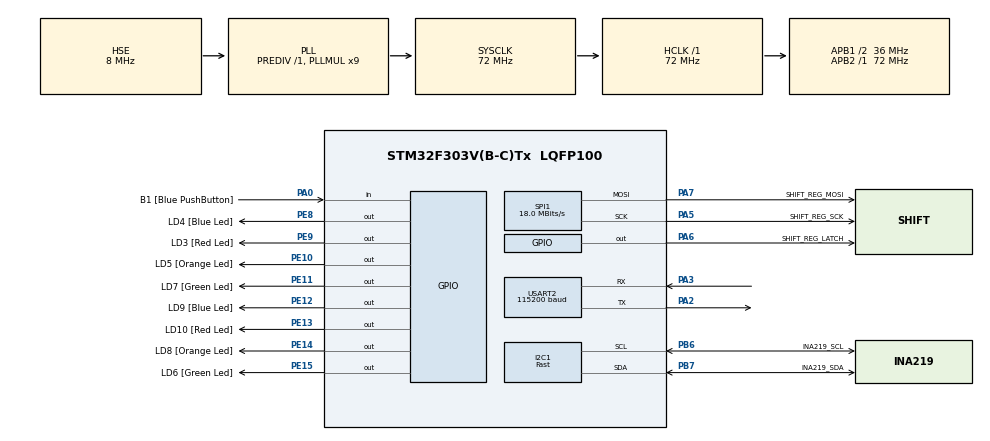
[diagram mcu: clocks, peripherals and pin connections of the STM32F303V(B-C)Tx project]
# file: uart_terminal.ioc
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Dma.Request0=USART2_TX
Dma.Request1=USART2_RX
Dma.Request2=SPI1_TX
Dma.SPI1_TX.2.Direction=DMA_MEMORY_TO_PERIPH
Dma.SPI1_TX.2.Instance=DMA1_Channel3
Dma.SPI1_TX.2.MemDataAlignment=DMA_MDATAALIGN_BYTE
Dma.SPI1_TX.2.MemInc=DMA_MINC_ENABLE
Dma.SPI1_TX.2.Mode=DMA_NORMAL
Dma.SPI1_TX.2.PeriphDataAlignment=DMA_PDATAALIGN_BYTE
Dma.SPI1_TX.2.PeriphInc=DMA_PINC_DISABLE
Dma.SPI1_TX.2.Priority=DMA_PRIORITY_MEDIUM
Dma.USART2_RX.1.Direction=DMA_PERIPH_TO_MEMORY
Dma.USART2_RX.1.Instance=DMA1_Channel6
Dma.USART2_RX.1.MemDataAlignment=DMA_MDATAALIGN_BYTE
Dma.USART2_RX.1.MemInc=DMA_MINC_ENABLE
Dma.USART2_RX.1.Mode=DMA_NORMAL
Dma.USART2_RX.1.PeriphDataAlignment=DMA_PDATAALIGN_BYTE
Dma.USART2_RX.1.PeriphInc=DMA_PINC_DISABLE
Dma.USART2_RX.1.Priority=DMA_PRIORITY_HIGH
Dma.USART2_TX.0.Direction=DMA_MEMORY_TO_PERIPH
Dma.USART2_TX.0.Instance=DMA1_Channel7
Dma.USART2_TX.0.MemDataAlignment=DMA_MDATAALIGN_BYTE
Dma.USART2_TX.0.MemInc=DMA_MINC_ENABLE
Dma.USART2_TX.0.Mode=DMA_NORMAL
Dma.USART2_TX.0.PeriphDataAlignment=DMA_PDATAALIGN_BYTE
Dma.USART2_TX.0.PeriphInc=DMA_PINC_DISABLE
Dma.USART2_TX.0.Priority=DMA_PRIORITY_HIGH
I2C1.I2C_Speed_Mode=I2C_Fast
I2C1.Timing=0x0000020B
Mcu.Family=STM32F3
Mcu.Name=STM32F303V(B-C)Tx
Mcu.Package=LQFP100
NVIC.DMA1_Channel3_IRQn=true\:0\:0\:false\:false\:true\:false\:true
NVIC.DMA1_Channel6_IRQn=true\:0\:0\:false\:false\:true\:false\:true
NVIC.DMA1_Channel7_IRQn=true\:0\:0\:false\:false\:true\:false\:true
NVIC.I2C1_ER_IRQn=true\:0\:0\:false\:false\:true\:true\:true
NVIC.I2C1_EV_IRQn=true\:0\:0\:false\:false\:true\:true\:true
NVIC.PriorityGroup=NVIC_PRIORITYGROUP_0
NVIC.SPI1_IRQn=true\:0\:0\:false\:false\:true\:true\:true
NVIC.TIM2_IRQn=true\:0\:0\:false\:false\:true\:true\:true
NVIC.USART2_IRQn=true\:0\:0\:false\:false\:true\:true\:true
PA0.GPIO_Label=B1 [Blue PushButton]
PA0.Signal=GPIO_Input
PA11.GPIO_Label=DM
PA11.Signal=USB_DM
PA12.GPIO_Label=DP
PA12.Signal=USB_DP
PA13.GPIO_Label=SWDIO
PA13.Mode=Serial_Wire
PA13.Signal=SYS_JTMS-SWDIO
PA14.GPIO_Label=SWCLK
PA14.Mode=Serial_Wire
PA14.Signal=SYS_JTCK-SWCLK
PA2.Mode=Asynchronous
PA2.Signal=USART2_TX
PA3.Mode=Asynchronous
PA3.Signal=USART2_RX
PA5.GPIO_Label=SHIFT_REG_SCK
PA5.Mode=TX_Only_Simplex_Unidirect_Master
PA5.Signal=SPI1_SCK
PA6.GPIO_Label=SHIFT_REG_LATCH
PA6.GPIO_PuPd=GPIO_PULLUP
PA6.GPIO_Speed=GPIO_SPEED_FREQ_HIGH
PA6.Signal=GPIO_Output
PA7.GPIO_Label=SHIFT_REG_MOSI
PA7.Mode=TX_Only_Simplex_Unidirect_Master
PA7.Signal=SPI1_MOSI
PB3.GPIO_Label=SWO
PB3.Signal=SYS_JTDO-TRACESWO
PB6.GPIO_Label=INA219_SCL
PB6.Mode=I2C
PB6.Signal=I2C1_SCL
PB7.GPIO_Label=INA219_SDA
PB7.Mode=I2C
PB7.Signal=I2C1_SDA
PC14-OSC32_IN.GPIO_Label=OSC32_IN
PC14-OSC32_IN.Signal=RCC_OSC32_IN
PC15-OSC32_OUT.GPIO_Label=OSC32_OUT
PC15-OSC32_OUT.Signal=RCC_OSC32_OUT
PE10.GPIO_Label=LD5 [Orange Led]
PE10.Signal=GPIO_Output
PE11.GPIO_Label=LD7 [Green Led]
PE11.Signal=GPIO_Output
PE12.GPIO_Label=LD9 [Blue Led]
PE12.Signal=GPIO_Output
PE13.GPIO_Label=LD10 [Red Led]
PE13.Signal=GPIO_Output
PE14.GPIO_Label=LD8 [Orange Led]
PE14.Signal=GPIO_Output
PE15.GPIO_Label=LD6 [Green Led]
PE15.Signal=GPIO_Output
PE8.GPIO_Label=LD4 [Blue Led]
PE8.Signal=GPIO_Output
PE9.GPIO_Label=LD3 [Red Led]
PE9.Signal=GPIO_Output
PF0-OSC_IN.GPIO_Label=OSC_IN
PF0-OSC_IN.Mode=HSE-External-Clock-Source
PF0-OSC_IN.Signal=RCC_OSC_IN
PF1-OSC_OUT.GPIO_Label=OSC_OUT
PF1-OSC_OUT.Signal=RCC_OSC_OUT
ProjectManager.HeapSize=0x200
ProjectManager.StackSize=0x400
ProjectManager.TargetToolchain=TrueSTUDIO
RCC.AHBFreq_Value=72000000
RCC.APB1CLKDivider=RCC_HCLK_DIV2
RCC.APB1Freq_Value=36000000
RCC.APB1TimFreq_Value=72000000
RCC.APB2Freq_Value=72000000
RCC.APB2TimFreq_Value=72000000
RCC.CortexFreq_Value=72000000
RCC.HCLKFreq_Value=72000000
RCC.HSE_VALUE=8000000
RCC.HSI_VALUE=8000000
RCC.LSE_VALUE=32768
RCC.PLLMUL=RCC_PLL_MUL9
RCC.PLLSourceVirtual=RCC_PLLSOURCE_HSE
RCC.SYSCLKFreq_VALUE=72000000
RCC.SYSCLKSourceVirtual=RCC_SYSCLKSOURCE_PLLCLK
RCC.USBFreq_Value=72000000
SPI1.BaudRatePrescaler=SPI_BAUDRATEPRESCALER_4
SPI1.CalculateBaudRate=18.0 MBits/s
SPI1.DataSize=SPI_DATASIZE_8BIT
SPI1.Direction=SPI_DIRECTION_2LINES
SPI1.Mode=SPI_MODE_MASTER
SPI1.VirtualType=VM_MASTER
TIM2.Period=9
TIM2.Prescaler=7199
USART2.BaudRate=115200
USART2.VirtualMode-Asynchronous=VM_ASYNC
VP_TIM2_VS_ClockSourceINT.Mode=Internal
board=STM32F3DISCOVERY

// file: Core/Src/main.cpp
/* USER CODE BEGIN Header */
/**
  ******************************************************************************
  * @file           : main.c
  * @brief          : Main program body
  ******************************************************************************
  * @attention
  *
  * <h2><center>&copy; Copyright (c) 2019 STMicroelectronics.
  * All rights reserved.</center></h2>
  *
  * This software component is licensed by ST under BSD 3-Clause license,
  * the "License"; You may not use this file except in compliance with the
  * License. You may obtain a copy of the License at:
  *                        opensource.org/licenses/BSD-3-Clause
  *
  ******************************************************************************
  */
/* USER CODE END Header */

#include "main.h"
#include "dma.h"
#include "i2c.h"
#include "spi.h"
#include "tim.h"
#include "usart.h"
#include "gpio.h"

/* USER CODE BEGIN Includes */
#include "../logger/Logger.h"
#include "../logger/uart_driver.h"
/* USER CODE END Includes */

void SystemClock_Config(void);

int main(void)
{

  /* MCU Configuration--------------------------------------------------------*/

  /* Reset of all peripherals, Initializes the Flash interface and the Systick. */
  HAL_Init();

  /* Configure the system clock */
  SystemClock_Config();

  /* Initialize all configured peripherals */
  MX_GPIO_Init();
  MX_DMA_Init();
  MX_USART2_UART_Init();
  MX_I2C1_Init();
  MX_SPI1_Init();
  MX_TIM2_Init();
  /* USER CODE BEGIN 2 */

  uart_driver_init();

  SDL::Logger& logger = SDL::Logger::getInstance();

  logger.print("Some test message send by uart logger object\n\r");
  logger.print(SDL::LogLevel::DEBUG, "Some debug info!\n\r");
  logger.print(SDL::LogLevel::INFO, "Some Info Message!\n\r");
  logger.print(SDL::LogLevel::ERROR, "Some Error Message!\n\r");

   /* USER CODE END 2 */

   /* Infinite loop */
   while (1)
   {

   }
}

void SystemClock_Config(void)
{
  RCC_OscInitTypeDef RCC_OscInitStruct = {0};
  RCC_ClkInitTypeDef RCC_ClkInitStruct = {0};
  RCC_PeriphCLKInitTypeDef PeriphClkInit = {0};

  /** Initializes the CPU, AHB and APB busses clocks
  */
  RCC_OscInitStruct.OscillatorType = RCC_OSCILLATORTYPE_HSI|RCC_OSCILLATORTYPE_HSE;
  RCC_OscInitStruct.HSEState = RCC_HSE_BYPASS;
  RCC_OscInitStruct.HSEPredivValue = RCC_HSE_PREDIV_DIV1;
  RCC_OscInitStruct.HSIState = RCC_HSI_ON;
  RCC_OscInitStruct.HSICalibrationValue = RCC_HSICALIBRATION_DEFAULT;
  RCC_OscInitStruct.PLL.PLLState = RCC_PLL_ON;
  RCC_OscInitStruct.PLL.PLLSource = RCC_PLLSOURCE_HSE;
  RCC_OscInitStruct.PLL.PLLMUL = RCC_PLL_MUL9;
  if (HAL_RCC_OscConfig(&RCC_OscInitStruct) != HAL_OK)
  {
    Error_Handler();
  }
  /** Initializes the CPU, AHB and APB busses clocks
  */
  RCC_ClkInitStruct.ClockType = RCC_CLOCKTYPE_HCLK|RCC_CLOCKTYPE_SYSCLK
                              |RCC_CLOCKTYPE_PCLK1|RCC_CLOCKTYPE_PCLK2;
  RCC_ClkInitStruct.SYSCLKSource = RCC_SYSCLKSOURCE_PLLCLK;
  RCC_ClkInitStruct.AHBCLKDivider = RCC_SYSCLK_DIV1;
  RCC_ClkInitStruct.APB1CLKDivider = RCC_HCLK_DIV2;
  RCC_ClkInitStruct.APB2CLKDivider = RCC_HCLK_DIV1;

  if (HAL_RCC_ClockConfig(&RCC_ClkInitStruct, FLASH_LATENCY_2) != HAL_OK)
  {
    Error_Handler();
  }
  PeriphClkInit.PeriphClockSelection = RCC_PERIPHCLK_USART2|RCC_PERIPHCLK_I2C1;
  PeriphClkInit.Usart2ClockSelection = RCC_USART2CLKSOURCE_PCLK1;
  PeriphClkInit.I2c1ClockSelection = RCC_I2C1CLKSOURCE_HSI;
  if (HAL_RCCEx_PeriphCLKConfig(&PeriphClkInit) != HAL_OK)
  {
    Error_Handler();
  }
}

void Error_Handler(void)
{
}

/************************ (C) COPYRIGHT STMicroelectronics *****END OF FILE****/
